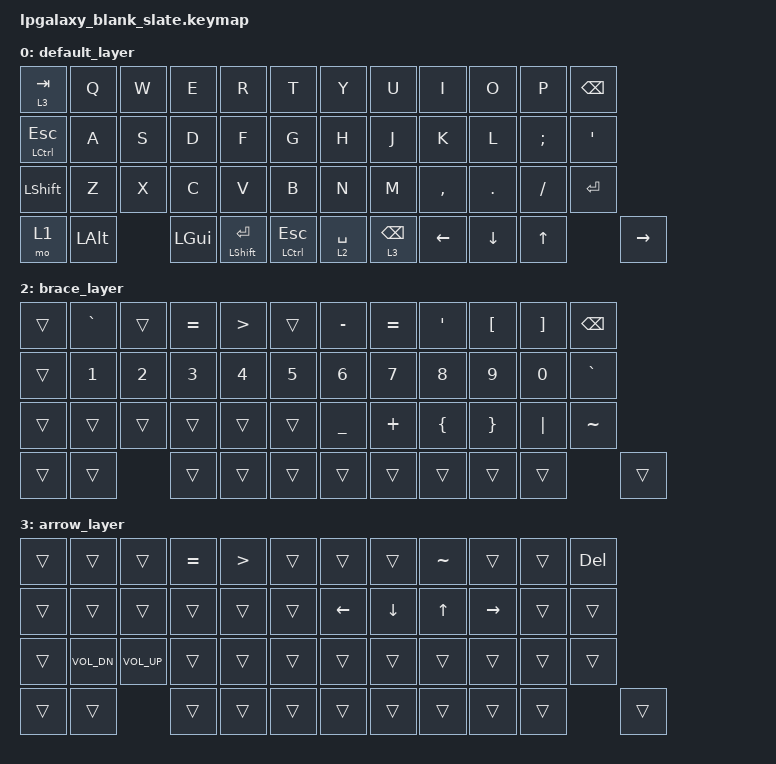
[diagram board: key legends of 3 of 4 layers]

/*
 * Copyright (c) 2022 Pete Johanson
 *
 * SPDX-License-Identifier: MIT
 */

#include <behaviors.dtsi>
#include <dt-bindings/zmk/keys.h>
#include <dt-bindings/zmk/bt.h>
#include <dt-bindings/zmk/outputs.h>

#define QWERTY_BASE 1

#define TBLE_ORTHO   1
// #define TBLE_MIT     1
// #define TBLE_DUAL_2U 1

#define NAV_L 1
#define NUM_L 2
#define SYM_L 3
#define MAX_L 4

// Using layer taps on thumbs, having quick tap as well helps w/ repeating space/backspace
&lt { quick_tap_ms = <200>; };

#define BT(n) BT_SEL n

/ {
    chosen {
       zmk,physical-layout =
                       &layout_ortho_4x12_1x2u;
    };
    combos {
        compatible = "zmk,combos";

        hmr_gui {
            bindings = <&kp LEFT_GUI>;
            key-positions = <19 21>;
        };

        hmr_gui_left {
            bindings = <&kp LEFT_GUI>;
            key-positions = <14 16>;
        };
    };
    keymap {
        compatible = "zmk,keymap";

        default_layer {
            // -----------------------------------------------------------------------------------------
            // |  TAB |  Q  |  W  |  E  |  R  |  T  |   |  Y  |  U   |  I  |  O  |  P  | BKSP |
            // | CTRL/ESC |  A  |  S  |  D  |  F  |  G  |   |  H  |  J   |  K  |  L  |  ;  |  '   |
            // | SHFT |  Z  |  X  |  C  |  V  |  B  |   |  N  |  M   |  ,  |  .  |  /  | ESC  |
            //                    | GUI | LWR | SPC |   | ENT | RSE  | ALT |

            bindings = <
&lt 3 TAB      &kp Q  &kp W  &kp E     &kp R                 &kp T               &kp Y        &kp U            &kp I      &kp O    &kp P     &kp BSPC
&mt LCTRL ESC  &kp A  &kp S  &kp D     &kp F                 &kp G               &kp H        &kp J            &kp K      &kp L    &kp SEMI  &kp SQT
&kp LSHFT      &kp Z  &kp X  &kp C     &kp V                 &kp B               &kp N        &kp M            &kp COMMA  &kp DOT  &kp FSLH  &kp ENTER
&mo 1          &kp LALT   &kp LGUI  &mt LEFT_SHIFT ENTER    &mt LCTRL ESCAPE     &lt 2 SPACE  &lt 3 BACKSPACE  &kp LEFT    &kp DOWN     &kp UP      &kp RIGHT
            >;
        };

        bt_layer {
            // -----------------------------------------------------------------------------------------
            // |  TAB |     |     |     |     |     |   |     |     |     |     |     | BKSP |
            // | BTCLR| BT1 | BT2 | BT3 | BT4 | BT5 |   | LFT | DWN |  UP | RGT |     |      |
            // | SHFT |     |     |     |     |     |   |     |     |     |     |     |      |
            //                    | GUI |     | SPC |   | ENT |     | ALT |

            bindings = <
&bt BT_CLR_ALL  &trans      &trans        &trans        &trans        &trans          &trans        &trans    &trans    &trans  &trans     &trans
&bt BT_CLR_ALL  &bt BT_CLR  &bt BT(0)  &bt BT(1)  &bt BT(2)   &bt BT(3)       &bt BT(4)  &kp LEFT  &kp DOWN  &kp UP  &kp RIGHT  &trans
&trans  &trans      &trans        &trans        &trans        &trans          &trans        &trans    &trans    &trans  &trans     &trans
&trans &trans  &trans &trans &trans  &trans &trans &trans  &trans &trans &trans 
        &trans        &kp LGUI      &trans          &kp SPACE     &kp RET   &trans
            >;
        };

        brace_layer {
            // -----------------------------------------------------------------------------------------
            // |  TAB |  !  |  @  |  #  |  $  |  %  |   |  ^  |  &  |  *  |  (  |  )  | BKSP |
            // | CTRL |     |     |     |     |     |   |  -  |  =  |  [  |  ]  |  \  |  `   |
            // | SHFT |     |     |     |     |     |   |  _  |  +  |  {  |  }  | "|" |  ~   |
            //                    | GUI |     | SPC |   | ENT |     | ALT |

            bindings = <
&trans  &kp GRAVE  &trans  &kp EQUAL  &kp GREATER_THAN  &trans    &kp MINUS  &kp EQUAL  &kp SINGLE_QUOTE  &kp LEFT_BRACKET  &kp RIGHT_BRACKET  &kp BSPC
&trans  &kp N1     &kp N2     &kp N3            &kp N4  &kp N5    &kp N6     &kp N7     &kp N8            &kp N9             &kp N0            &kp GRAVE
&trans  &trans     &trans     &trans            &trans  &trans    &kp UNDER  &kp PLUS   &kp LBRC          &kp RBRC           &kp PIPE          &kp TILDE
&trans &trans  &trans &trans &trans  &trans &trans &trans  &trans &trans &trans 
            >;
        };

        arrow_layer {
            bindings = <
&trans  &trans   &trans  &kp EQUAL &kp GREATER_THAN  &trans    &trans            &trans    &kp TILDE     &trans     &trans  &kp DEL
&trans  &trans        &trans           &trans            &trans  &trans    &kp LEFT          &kp DOWN  &kp UP_ARROW  &kp RIGHT  &trans  &trans
&trans  &kp C_VOL_DN  &kp C_VOLUME_UP  &trans            &trans  &trans    &trans            &trans    &trans        &trans     &trans  &trans
&trans &trans  &trans &trans &trans  &trans &trans &trans  &trans &trans &trans 
            >;
        };
    };


};
